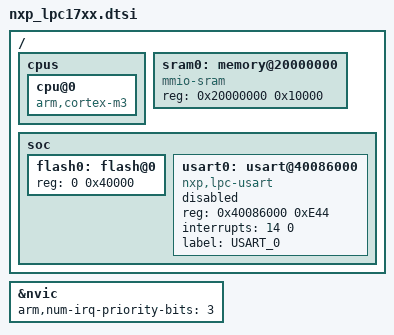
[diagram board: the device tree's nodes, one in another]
/*
 * Copyright (c) 2017, NXP
 *
 * SPDX-License-Identifier: Apache-2.0
 */

#include <arm/armv7-m.dtsi>

/ {
	cpus {
		cpu@0 {
			compatible = "arm,cortex-m3";
		};
		
	};

	sram0:memory@20000000 {
		compatible = "mmio-sram";
		reg = <0x20000000 0x10000>;
	};

	soc {

		flash0:flash@0 {
			reg = <0 0x40000>;
		};

		usart0:usart@40086000 {
			compatible = "nxp,lpc-usart";
			reg = <0x40086000 0xE44>;
			interrupts = <14 0>;
			label = "USART_0";
			status = "disabled";
		};
	};
};

&nvic {
	arm,num-irq-priority-bits = <3>;
};
